AUTOSAR XML (schema 314)
package /ComponentType
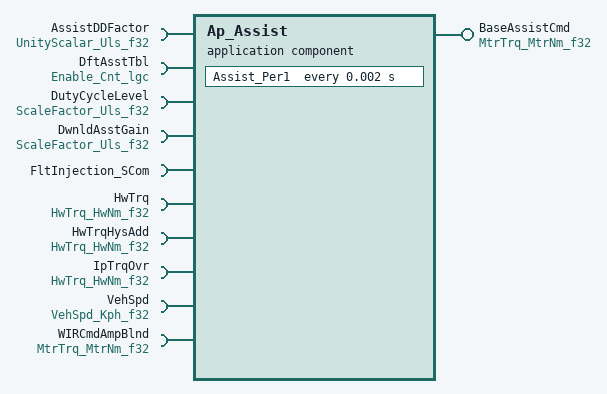
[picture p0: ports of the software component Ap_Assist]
  application software component type Ap_Assist
    provide port BaseAssistCmd: unqueued-sender-com-spec{data-element=MtrNm_f32, can-invalidate=false, init-value=D_ZERO_ULS_F32}, provided-interface=MtrTrq_MtrNm_f32
    10 x require port:
      AssistDDFactor: unqueued-receiver-com-spec{data-element=Uls_f32, init-value=D_ONE_ULS_F32}, required-interface=UnityScalar_Uls_f32
      DftAsstTbl: unqueued-receiver-com-spec{data-element=Cnt_lgc, init-value=D_FALSE_CNT_LGC}, required-interface=Enable_Cnt_lgc
      DutyCycleLevel: unqueued-receiver-com-spec{data-element=Uls_f32, init-value=D_ZERO_ULS_F32}, required-interface=ScaleFactor_Uls_f32
      DwnldAsstGain: unqueued-receiver-com-spec{data-element=Uls_f32, init-value=D_ZERO_ULS_F32}, required-interface=ScaleFactor_Uls_f32
      FltInjection_SCom: client-com-spec=FltInjection, required-interface=FltInjection_SCom
      HwTrq: unqueued-receiver-com-spec{data-element=HwNm_f32, init-value=D_ZERO_ULS_F32}, required-interface=HwTrq_HwNm_f32
      HwTrqHysAdd: unqueued-receiver-com-spec{data-element=HwNm_f32, init-value=D_ZERO_ULS_F32}, required-interface=HwTrq_HwNm_f32
      IpTrqOvr: unqueued-receiver-com-spec{data-element=HwNm_f32, init-value=D_ZERO_ULS_F32}, required-interface=HwTrq_HwNm_f32
      VehSpd: unqueued-receiver-com-spec{data-element=Kph_f32, init-value=D_ZERO_ULS_F32}, required-interface=VehSpd_Kph_f32
      WIRCmdAmpBlnd: unqueued-receiver-com-spec{data-element=MtrNm_f32, init-value=D_ZERO_ULS_F32}, required-interface=MtrTrq_MtrNm_f32
  internal behavior Ap_Assist_InternalBehavior: component=Ap_Assist
    timing event TMT_Assist_Per1: start-on-event=Assist_Per1, period=0.002
    port-api-options:
      enable-take-address=false, indirect-api=false, port=AssistDDFactor
      enable-take-address=false, indirect-api=false, port=BaseAssistCmd
      enable-take-address=false, indirect-api=false, port=DftAsstTbl
      enable-take-address=false, indirect-api=false, port=DutyCycleLevel
      enable-take-address=false, indirect-api=false, port=DwnldAsstGain
      enable-take-address=false, indirect-api=false, port=FltInjection_SCom
      enable-take-address=false, indirect-api=false, port=HwTrq
      enable-take-address=false, indirect-api=false, port=HwTrqHysAdd
      enable-take-address=false, indirect-api=false, port=IpTrqOvr
      enable-take-address=false, indirect-api=false, port=VehSpd
      enable-take-address=false, indirect-api=false, port=WIRCmdAmpBlnd
    runnable Assist_Per1
      9 x data read access:
        READ_AssistDDFactor_Uls_f32: data-element=AssistDDFactor.Uls_f32
        READ_DftAsstTbl_Cnt_lgc: data-element=DftAsstTbl.Cnt_lgc
        READ_DutyCycleLevel_Uls_f32: data-element=DutyCycleLevel.Uls_f32
        READ_DwnldAsstGain_Uls_f32: data-element=DwnldAsstGain.Uls_f32
        READ_HwTrq_HwNm_f32: data-element=HwTrq.HwNm_f32
        READ_HwTrqHysAdd_HwNm_f32: data-element=HwTrqHysAdd.HwNm_f32
        READ_IpTrqOvr_HwNm_f32: data-element=IpTrqOvr.HwNm_f32
        READ_VehSpd_Kph_f32: data-element=VehSpd.Kph_f32
        READ_WIRCmdAmpBlnd_MtrNm_f32: data-element=WIRCmdAmpBlnd.MtrNm_f32
      data write access WRITE_BaseAssistCmd_MtrNm_f32: data-element=BaseAssistCmd.MtrNm_f32
      sync call SC_FltInjection_SCom_FltInjection: operation=FltInjection_SCom.FltInjection, timeout=0
  swc implementation Ap_Assist_Implementation: behavior=Ap_Assist_InternalBehavior
    code-descriptors:
      code Code: type=SRC
